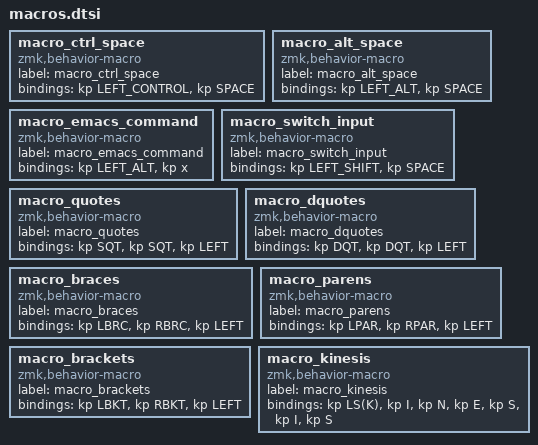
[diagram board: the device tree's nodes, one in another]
macro_ctrl_space: macro_ctrl_space{
compatible = "zmk,behavior-macro";
label = "macro_ctrl_space";
#binding-cells = <0>;
bindings = <&kp LEFT_CONTROL>,<&kp SPACE>;
};
macro_alt_space: macro_alt_space{
compatible = "zmk,behavior-macro";
label = "macro_alt_space";
#binding-cells = <0>;
bindings = <&kp LEFT_ALT>, <&kp SPACE>;
};
macro_emacs_command: macro_emacs_command{
compatible = "zmk,behavior-macro";
label = "macro_emacs_command";
#binding-cells = <0>;
bindings = <&kp LEFT_ALT>, <&kp x>;
};
macro_switch_input: macro_switch_input{
compatible = "zmk,behavior-macro";
label = "macro_switch_input";
#binding-cells = <0>;
bindings = <&kp LEFT_SHIFT>, <&kp SPACE>;
};
macro_quotes: macro_quotes{
compatible = "zmk,behavior-macro";
label = "macro_quotes";
#binding-cells = <0>;
bindings = <&kp SQT>, <&kp SQT>, <&kp LEFT>;
};
macro_dquotes: macro_dquotes{
compatible = "zmk,behavior-macro";
label = "macro_dquotes";
#binding-cells = <0>;
bindings = <&kp DQT>, <&kp DQT>, <&kp LEFT>;
};
macro_braces: macro_braces{
compatible = "zmk,behavior-macro";
label = "macro_braces";
#binding-cells = <0>;
bindings = <&kp LBRC>, <&kp RBRC>, <&kp LEFT>;
};
macro_parens: macro_parens{
compatible = "zmk,behavior-macro";
label = "macro_parens";
#binding-cells = <0>;
bindings = <&kp LPAR>, <&kp RPAR>, <&kp LEFT>;
};
macro_brackets: macro_brackets{
compatible = "zmk,behavior-macro";
label = "macro_brackets";
#binding-cells = <0>;
bindings = <&kp LBKT>, <&kp RBKT>, <&kp LEFT>;
};
macro_kinesis: macro_kinesis{
compatible = "zmk,behavior-macro";
label = "macro_kinesis";
#binding-cells = <0>;
bindings = <&kp LS(K)>, <&kp I>, <&kp N>, <&kp E>, <&kp S>, <&kp I>, <&kp S>;
};
